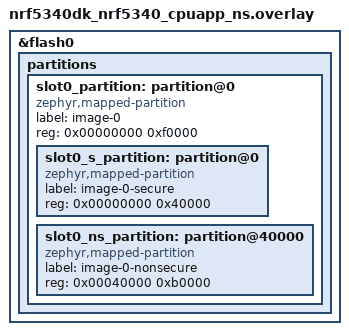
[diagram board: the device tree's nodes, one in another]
/*
 * Copyright (c) 2026 Nordic Semiconductor ASA
 *
 * SPDX-License-Identifier: LicenseRef-Nordic-5-Clause
 */

/*
 * No bootloader is built in this configuration.
 * The default nRF5340 partition layout reserves the first 64 KB for MCUboot.
 * The TF-M storage and settings partitions from the board devicetree
 * (0xf0000 onwards) are kept and still used.
 */
/delete-node/ &boot_partition;
/delete-node/ &slot0_partition;
/delete-node/ &slot1_partition;

&flash0 {
	partitions {
		slot0_partition: partition@0 {
			compatible = "zephyr,mapped-partition";
			label = "image-0";
			reg = <0x00000000 0xf0000>;
			ranges = <0x0 0x0 0xf0000>;
			#address-cells = <1>;
			#size-cells = <1>;

			slot0_s_partition: partition@0 {
				compatible = "zephyr,mapped-partition";
				label = "image-0-secure";
				reg = <0x00000000 0x40000>;
			};

			slot0_ns_partition: partition@40000 {
				compatible = "zephyr,mapped-partition";
				label = "image-0-nonsecure";
				reg = <0x00040000 0xb0000>;
			};
		};
	};
};
